AUTOSAR XML (schema 00047)
package /App_WdgM
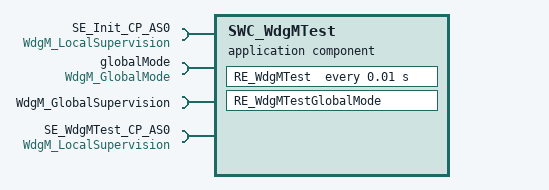
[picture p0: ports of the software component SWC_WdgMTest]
  application sw component type SWC_WdgMTest
    4 x require port:
      SE_Init_CP_AS0: client-com-spec=CheckpointReached, required-interface=WdgM_LocalSupervision
      globalMode: mode-switch-receiver-com-spec{mode-group=currentMode, supports-asynchronous-mode-switch=false}, required-interface=WdgM_GlobalMode
      WdgM_GlobalSupervision: required-com-specs=[GetFirstExpiredSEID, GetGlobalStatus, SetMode, PerformReset, GetMode], required-interface=WdgM_GlobalSupervision
      SE_WdgMTest_CP_AS0: client-com-spec=CheckpointReached, required-interface=WdgM_LocalSupervision
    behavior InternalBehavior: data-type-mapping=WdgM_Mode, handle-termination-and-restart=NO-SUPPORT
      timing event TE_RE_WdgMTest: start-on-event=RE_WdgMTest, period=0.01
      4 x swc mode switch event, all with start-on-event=RE_WdgMTestGlobalMode, activation=ON-ENTRY:
        SMSE_Entry_RE_WdgMTestGlobalMode_globalMode_currentMode_SUPERVISION_EXPIRED: mode=globalMode.currentMode.SUPERVISION_EXPIRED
        SMSE_Entry_RE_WdgMTestGlobalMode_globalMode_currentMode_SUPERVISION_FAILED: mode=globalMode.currentMode.SUPERVISION_FAILED
        SMSE_Entry_RE_WdgMTestGlobalMode_globalMode_currentMode_SUPERVISION_OK: mode=globalMode.currentMode.SUPERVISION_OK
        SMSE_Entry_RE_WdgMTestGlobalMode_globalMode_currentMode_SUPERVISION_STOPPED: mode=globalMode.currentMode.SUPERVISION_STOPPED
      runnable RE_WdgMTest
        4 x sync call:
          SSCP_RE_WdgMTest_WdgM_GlobalSupervision_SetMode: operation=WdgM_GlobalSupervision.SetMode
          SSCP_RE_WdgMTest_WdgM_GlobalSupervision_GetFirstExpiredSEID: operation=WdgM_GlobalSupervision.GetFirstExpiredSEID, timeout=0.0
          SSCP_RE_WdgMTest_WdgM_GlobalSupervision_GetGlobalStatus: operation=WdgM_GlobalSupervision.GetGlobalStatus, timeout=0.0
          SSCP_RE_WdgMTest_SE_Init_CP_AS0_CheckpointReached: operation=SE_Init_CP_AS0.CheckpointReached
      runnable RE_WdgMTestGlobalMode
        mode-access-point mode-group=globalMode.currentMode:
          ident MRAP_RE_WdgMTestGlobalMode_globalMode_currentMode
        sync call SSCP_RE_WdgMTestGlobalMode_WdgM_GlobalSupervision_GetFirstExpiredSEID: operation=WdgM_GlobalSupervision.GetFirstExpiredSEID, timeout=0.0
        sync call SSCP_RE_WdgMTestGlobalMode_WdgM_GlobalSupervision_GetGlobalStatus: operation=WdgM_GlobalSupervision.GetGlobalStatus, timeout=0.0
